# COREAON_PRM register map
Vendor: Texas Instruments
Peripheral module from a debugger description file (folder omap5430_ES2_PUBLIC).
Registers are 32-bit, access per field, reset 0x1 unless marked. A register's access mark holds for its fields unless they carry their own. Offsets are as the file gives them; lines under a group give offsets from that group; [hi:lo] are bit positions; {n}, {i} and the like mark numbered series; 'fields as' and 'values as' point back to an identical list; <NAME> marks a mode.

## COREAON_PRM
0x28 PM_COREAON_SMARTREFLEX_MPU_WKDEP — This register controls wakeup dependency based on SMARTREFLEX_MPU service requests.
  [0] WKUPDEP_SMARTREFLEX_MPU_MPU rw — Wakeup dependency from SR_MPU module (SWakeup signal) towards MPU + L3MAIN1 + L4CFG domains
    0=Disabled (Dependency is disabled); 1=Enabled (Dependency is enabled)
0x2C RM_COREAON_SMARTREFLEX_MPU_CONTEXT access not given — This register contains dedicated SMARTREFLEX_MPU context statuses. [warm reset insensitive]
  [0] LOSTCONTEXT_DFF — Specify if DFF-based context has been lost due to a previous power transition or other reset source. (set upon assertion of COREAON_RST signal) (access RW W1toClr)
    0=Maintained (Context has been maintained); 1=Lost (Context has been lost)
0x30 PM_COREAON_SMARTREFLEX_MM_WKDEP reset 0x0 — This register controls wakeup dependency based on SMARTREFLEX_MM service requests.
  [0] WKUPDEP_SMARTREFLEX_MM_MPU rw — Wakeup dependency from SMARTREFLEX_MM module (SWakeup signal) towards MPU + L3_MAIN1 + L4_CFG domains
    values as PM_COREAON_SMARTREFLEX_MPU_WKDEP.WKUPDEP_SMARTREFLEX_MPU_MPU
0x34 RM_COREAON_SMARTREFLEX_MM_CONTEXT access not given — This register contains dedicated SMARTREFLEX_MM context statuses. [warm reset insensitive]
  [0] LOSTCONTEXT_DFF — Specify if DFF-based context has been lost due to a previous power transition or other reset source. (set upon assertion of Always_on_CORE_RST signal) (access RW W1toClr)
    values as RM_COREAON_SMARTREFLEX_MPU_CONTEXT.LOSTCONTEXT_DFF
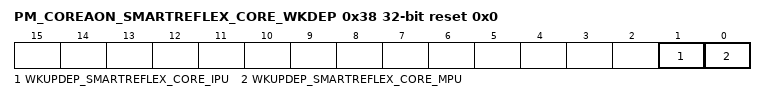
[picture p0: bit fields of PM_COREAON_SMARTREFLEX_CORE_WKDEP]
0x38 PM_COREAON_SMARTREFLEX_CORE_WKDEP reset 0x0 — This register controls wakeup dependency based on SMARTREFLEX_CORE service requests.
  [1] WKUPDEP_SMARTREFLEX_CORE_IPU rw — Wakeup dependency from SMARTREFLEX_CORE module (SWakeup signal) towards IPU + L3_MAIN2 + L3_MAIN1 + L4_CFG domains
    values as PM_COREAON_SMARTREFLEX_MPU_WKDEP.WKUPDEP_SMARTREFLEX_MPU_MPU
  [0] WKUPDEP_SMARTREFLEX_CORE_MPU rw — Wakeup dependency from SMARTREFLEX_CORE module (SWakeup signal) towards MPU + L3_MAIN1 + L4_CFG domains
    values as PM_COREAON_SMARTREFLEX_MPU_WKDEP.WKUPDEP_SMARTREFLEX_MPU_MPU
0x3C RM_COREAON_SMARTREFLEX_CORE_CONTEXT access not given — This register contains dedicated SMARTREFLEX_CORE context statuses. [warm reset insensitive]
  fields as RM_COREAON_SMARTREFLEX_MPU_CONTEXT
